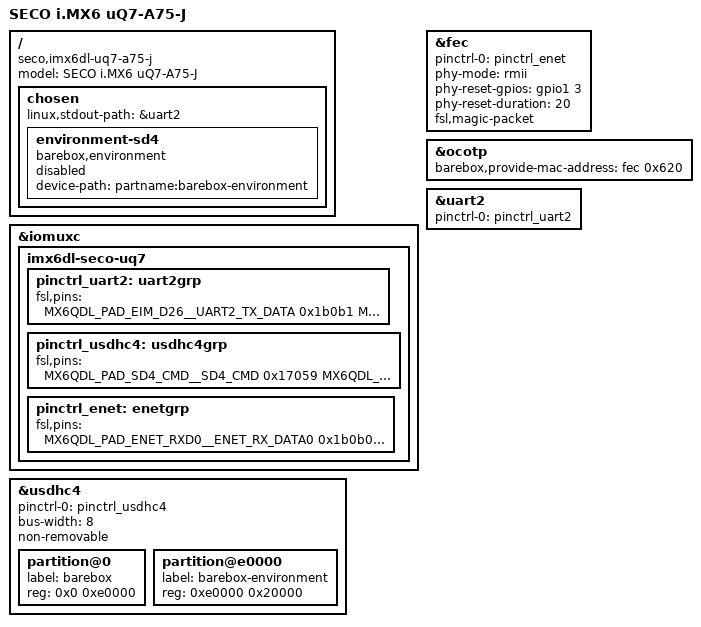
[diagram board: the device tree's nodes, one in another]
/*
 * Copyright 2011 Freescale Semiconductor, Inc.
 * Copyright 2011 Linaro Ltd.
 *
 * The code contained herein is licensed under the GNU General Public
 * License. You may obtain a copy of the GNU General Public License
 * Version 2 or later at the following locations:
 *
 * http://www.opensource.org/licenses/gpl-license.html
 * http://www.gnu.org/copyleft/gpl.html
 */

/dts-v1/;
#include <dt-bindings/gpio/gpio.h>
#include <dt-bindings/input/input.h>
#include <arm/imx6dl.dtsi>
#include "imx6dl.dtsi"

/ {
	model = "SECO i.MX6 uQ7-A75-J";
	compatible = "seco,imx6dl-uq7-a75-j", "fsl,imx6dl";

	chosen {
		linux,stdout-path = &uart2;

		environment-sd4 {
			compatible = "barebox,environment";
			device-path = &usdhc4, "partname:barebox-environment";
			status = "disabled";
		};
	};
};

&iomuxc {
	pinctrl-names = "default";

	imx6dl-seco-uq7 {
		pinctrl_uart2: uart2grp {
			fsl,pins = <
				MX6QDL_PAD_EIM_D26__UART2_TX_DATA	0x1b0b1
				MX6QDL_PAD_EIM_D27__UART2_RX_DATA	0x1b0b1
			>;
		};

		pinctrl_usdhc4: usdhc4grp {
			fsl,pins = <
				MX6QDL_PAD_SD4_CMD__SD4_CMD		0x17059
				MX6QDL_PAD_SD4_CLK__SD4_CLK		0x10059
				MX6QDL_PAD_SD4_DAT0__SD4_DATA0		0x17059
				MX6QDL_PAD_SD4_DAT1__SD4_DATA1		0x17059
				MX6QDL_PAD_SD4_DAT2__SD4_DATA2		0x17059
				MX6QDL_PAD_SD4_DAT3__SD4_DATA3		0x17059
				MX6QDL_PAD_SD4_DAT4__SD4_DATA4		0x17059
				MX6QDL_PAD_SD4_DAT5__SD4_DATA5		0x17059
				MX6QDL_PAD_SD4_DAT6__SD4_DATA6		0x17059
				MX6QDL_PAD_SD4_DAT7__SD4_DATA7		0x17059
			>;
		};

		pinctrl_enet: enetgrp {
			fsl,pins = <
				MX6QDL_PAD_ENET_RXD0__ENET_RX_DATA0	0x1b0b0
				MX6QDL_PAD_ENET_RXD1__ENET_RX_DATA1	0x1b0b0
				MX6QDL_PAD_ENET_TX_EN__ENET_TX_EN	0x1b0b0
				MX6QDL_PAD_ENET_TXD0__ENET_TX_DATA0	0x1b0b0
				MX6QDL_PAD_ENET_TXD1__ENET_TX_DATA1	0x1b0b0
				MX6QDL_PAD_ENET_MDC__ENET_MDC		0x1b0b0
				MX6QDL_PAD_ENET_MDIO__ENET_MDIO		0x1b0b0
				MX6QDL_PAD_GPIO_3__GPIO1_IO03		0x1f071
				MX6QDL_PAD_GPIO_2__GPIO1_IO02		0x1f071
				MX6QDL_PAD_ENET_RX_ER__ENET_RX_ER	0x1b0b0
				MX6QDL_PAD_GPIO_16__ENET_REF_CLK	0x1b0b0
				MX6QDL_PAD_ENET_CRS_DV__ENET_RX_EN	0x1b0b0
				MX6QDL_PAD_ENET_REF_CLK__GPIO1_IO23	0x1b0b0
			>;
		};
	};
};

&fec {
	pinctrl-names = "default";
	pinctrl-0 = <&pinctrl_enet>;
	phy-mode = "rmii";
	phy-reset-gpios = <&gpio1 3 0>;
	phy-reset-duration = <20>;
	fsl,magic-packet;
	status = "okay";
};

&ocotp {
	barebox,provide-mac-address = <&fec 0x620>;
};

&uart2 {
	pinctrl-names = "default";
	pinctrl-0 = <&pinctrl_uart2>;
	status = "okay";
};

&usdhc4 {
	pinctrl-names = "default";
	pinctrl-0 = <&pinctrl_usdhc4>;
	bus-width = <8>;
	non-removable;
	status = "okay";

	#address-cells = <1>;
	#size-cells = <1>;

	partition@0 {
		label = "barebox";
		reg = <0x0 0xe0000>;
	};

	partition@e0000 {
		label = "barebox-environment";
		reg = <0xe0000 0x20000>;
	};
};
